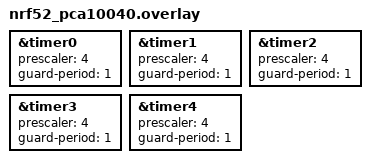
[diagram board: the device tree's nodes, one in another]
&timer0 {
	prescaler = <4>;
	guard-period = <1>;
};

&timer1 {
	prescaler = <4>;
	guard-period = <1>;
};

&timer2 {
	prescaler = <4>;
	guard-period = <1>;
};

&timer3 {
	prescaler = <4>;
	guard-period = <1>;
};

&timer4 {
	prescaler = <4>;
	guard-period = <1>;
};
